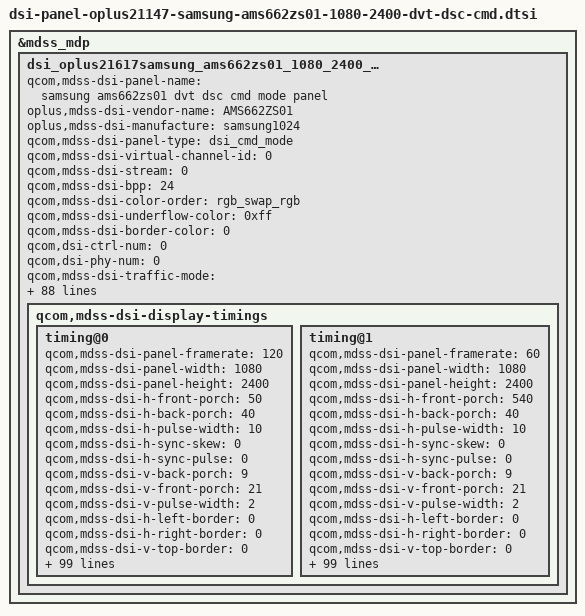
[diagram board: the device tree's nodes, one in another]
&mdss_mdp {
	dsi_oplus21617samsung_ams662zs01_1080_2400_cmd_dvt: qcom,mdss_dsi_oplus21617samsung_ams662zs01_1080_2400_cmd_dvt {
		qcom,mdss-dsi-panel-name = "samsung ams662zs01 dvt dsc cmd mode panel";
		oplus,mdss-dsi-vendor-name = "AMS662ZS01";
		oplus,mdss-dsi-manufacture = "samsung1024";
		qcom,mdss-dsi-panel-type = "dsi_cmd_mode";
		qcom,mdss-dsi-virtual-channel-id = <0>;
		qcom,mdss-dsi-stream = <0>;
		qcom,mdss-dsi-bpp = <24>;
		qcom,mdss-dsi-color-order = "rgb_swap_rgb";
		qcom,mdss-dsi-underflow-color = <0xff>;
		qcom,mdss-dsi-border-color = <0>;
		qcom,dsi-ctrl-num = <0>;
		qcom,dsi-phy-num = <0>;
		qcom,mdss-dsi-traffic-mode = "non_burst_sync_event";
		qcom,mdss-dsi-lane-map = "lane_map_0123";
		qcom,mdss-dsi-bllp-eof-power-mode;
		qcom,mdss-dsi-bllp-power-mode;
		qcom,mdss-dsi-lane-0-state;
		qcom,mdss-dsi-lane-1-state;
		qcom,mdss-dsi-lane-2-state;
		qcom,mdss-dsi-lane-3-state;
		qcom,mdss-dsi-dma-trigger = "trigger_sw";
		qcom,mdss-dsi-mdp-trigger = "none";
		qcom,mdss-dsi-reset-sequence = <1 10>, <0 10>, <1 10>;

		qcom,mdss-dsi-te-pin-select = <1>;
		qcom,mdss-dsi-te-dcs-command = <1>;
		qcom,mdss-dsi-te-check-enable;
		qcom,mdss-dsi-te-using-te-pin;
		qcom,mdss-dsi-lp11-init;
		qcom,mdss-dsi-wr-mem-start = <0x2c>;
		qcom,mdss-dsi-wr-mem-continue = <0x3c>;
		qcom,mdss-dsi-panel-hdr-enabled;
		qcom,mdss-dsi-panel-hdr-color-primaries = <15635 16450 34000 16000 13250 34500 7500 3000>;
		qcom,mdss-dsi-panel-peak-brightness = <5400000>;
		qcom,mdss-dsi-panel-blackness-level = <2000>;
		qcom,mdss-pan-physical-width-dimension = <70>;
		qcom,mdss-pan-physical-height-dimension = <153>;
		qcom,esd-check-enabled;
		qcom,mdss-dsi-panel-status-check-mode = "reg_read";
		qcom,mdss-dsi-panel-status-command = [06 01 00 01 05 00 02 0A 00
							06 01 00 01 05 00 02 05 00
							06 01 00 01 05 00 02 03 00
							06 01 00 01 05 00 02 0e 00];
		qcom,mdss-dsi-panel-status-command-state = "dsi_lp_mode";
		qcom,mdss-dsi-panel-status-value = <0x9f 0x00 0x01 0x80>;
		qcom,mdss-dsi-panel-status-read-length = <1 1 1 1>;
		oplus,esd-check-flag-enabled;
		oplus,esd-err-flag-gpio = <&tlmm 84 0>;
		oplus,esd-err-trigger-polarity = <1>;
		qcom,dynamic-mode-switch-enabled;
		qcom,dynamic-mode-switch-type = "dynamic-resolution-switch-immediate";
		qcom,mdss-dsi-display-timings {
			timing@0 {
				qcom,mdss-dsi-panel-framerate = <120>;
//				qcom,mdss-dsi-panel-clockrate = <830000000>;
				qcom,mdss-dsi-panel-width = <1080>;
				qcom,mdss-dsi-panel-height = <2400>;
				qcom,mdss-dsi-h-front-porch = <50>;
				qcom,mdss-dsi-h-back-porch = <40>;
				qcom,mdss-dsi-h-pulse-width = <10>;
				qcom,mdss-dsi-h-sync-skew = <0>;
				qcom,mdss-dsi-h-sync-pulse = <0>;
				qcom,mdss-dsi-v-back-porch = <9>;
				qcom,mdss-dsi-v-front-porch = <21>;
				qcom,mdss-dsi-v-pulse-width = <2>;
				qcom,mdss-dsi-h-left-border = <0>;
				qcom,mdss-dsi-h-right-border = <0>;
				qcom,mdss-dsi-v-top-border = <0>;
				qcom,mdss-dsi-v-bottom-border = <0>;
				qcom,mdss-dsi-panel-jitter = <0x4 0x1>;

				oplus,fod-on-vblank = <0>;
				oplus,fod-off-vblank = <1>;
				qcom,mdss-dsi-timing-switch-command = [
					//120hz Transition
					39 01 00 00 00 00 03 F0 5A 5A
					39 01 00 00 00 00 03 60 08 00
					39 01 00 00 00 00 02 F7 0F
					39 01 00 00 00 00 03 F0 A5 A5
				];
				qcom,mdss-dsi-fps-switch-command = [
					39 01 00 00 00 00 03 F0 5A 5A
					39 01 00 00 00 00 03 B0 28 F2
					39 01 00 00 00 00 02 F2 CE
					39 01 00 00 00 00 04 B0 01 B4 65
					39 01 00 00 00 00 21 65 09 70 09 28 09 03 08 98 08 2C 07 BF 06 EA 06 12 05 3A 04 62 03 8B 02 B2 01 6D 00 28 00 28 00 28
					39 01 00 00 00 00 04 B0 00 28 F2
					39 01 00 00 00 00 02 F2 C6
					39 01 00 00 00 00 03 60 08 00
					39 01 00 00 00 00 03 B0 08 F2
					39 01 00 00 00 00 02 F2 04
					39 01 00 00 00 00 02 F7 0F
					39 01 00 00 00 00 03 F0 A5 A5
				];
				qcom,mdss-dsi-on-command = [
					//DSC Setting
					39 01 00 00 00 00 81 9E
					11 00 00 89 30 80 09 60
					04 38 00 1E 02 1C 02 1C
					02 00 02 0E 00 20 02 E3
					00 07 00 0C 03 50 03 64
					18 00 10 F0 03 0C 20 00
					06 0B 0B 33 0E 1C 2A 38
					46 54 62 69 70 77 79 7B
					7D 7E 01 02 01 00 09 40
					09 BE 19 FC 19 FA 19 F8
					1A 38 1A 78 1A B6 2A F6
					2B 34 2B 74 3B 74 6B F4
					00 00 00 00 00 00 00 00
					00 00 00 00 00 00 00 00
					00 00 00 00 00 00 00 00
					00 00 00 00 00 00 00 00
					00 00 00 00 00 00 00 00
					39 01 00 00 00 00 02 C2 14
					39 01 00 00 00 00 02 9D 01
					//Sleep Out(11h)
					05 01 00 00 79 00 01 11
					//TE ON
					39 01 00 00 00 00 02 35 00
					//CASET/PASET Setting
					39 01 00 00 00 00 05 2A 00 00 04 37
					39 01 00 00 00 00 05 2B 00 00 09 5F
					//FQ CON Setting
					39 01 00 00 00 00 03 F0 5A 5A
					39 01 00 00 00 00 03 B0 27 F2
					39 01 00 00 00 00 02 F2 00
					39 01 00 00 00 00 03 F0 A5 A5
					//Frequency Setting
					39 01 00 00 00 00 03 F0 5A 5A
					39 01 00 00 00 00 03 60 08 00
					39 01 00 00 00 00 02 F7 0F
					39 01 00 00 00 00 03 F0 A5 A5
					//Seed mode 0
					39 01 00 00 00 00 03 f0 5a 5a
					39 01 00 00 00 00 03 b0 03 8f
					39 01 00 00 00 00 02 8f 05
					39 01 00 00 00 00 03 b0 28 f2
					39 01 00 00 00 00 02 f2 ce
					39 01 00 00 00 00 04 b0 01 18 68
					39 01 00 00 00 00 0f 68 e2 1a 1a 1a 82 04 f0 80 00 00 00 00 ff 00
					39 01 00 00 00 00 04 b0 00 28 f2
					39 01 00 00 00 00 02 f2 c6
					39 01 00 00 00 00 03 f0 a5 a5
					39 01 00 00 00 00 03 f0 5a 5a
					39 01 00 00 00 00 04 72 2c 21 00
					39 01 00 00 00 00 02 f8 00
					39 01 00 00 00 00 02 5d 06
					39 01 00 00 00 00 02 62 00
					39 01 00 00 00 00 03 b0 01 62
					39 01 00 00 00 00 16 62 C3 02 00 10 F0 04 06 01 e0 26 e9 f2 f7 07 fc E5 F0 02 FE FF FF
					39 01 00 00 18 00 04 72 2c 01 00
					39 01 00 00 00 00 03 f0 a5 a5
					/*OSC*/
					//39 01 00 00 00 00 03 F0 5A 5A
					//39 01 00 00 00 00 03 FC 5A 5A
					//39 01 00 00 00 00 03 B0 66 C5
					//39 01 00 00 00 00 03 C5 00 8C
					//39 01 00 00 00 00 03 B0 2A C5
					//39 01 00 00 00 00 05 C5 0D 10 80 45
					//39 01 00 00 00 00 03 B0 2E C5
					//39 01 00 00 00 00 03 C5 73 64
					//39 01 00 00 00 00 03 F0 A5 A5
					//39 01 00 00 00 00 03 FC A5 A5
					//BACKLIGHT
					39 01 00 00 00 00 02 53 20    //1 frame
				];

				qcom,mdss-dsi-off-command= [
					/* AOD off */
					39 01 00 00 00 00 03 F0 5A 5A
					15 01 00 00 00 00 02 91 02
					15 01 00 00 00 00 02 53 20
					39 01 00 00 00 00 03 F0 A5 A5
					05 01 00 00 0B 00 01 28
					05 01 00 00 79 00 01 10];
				qcom,mdss-dsi-post-on-backlight = [
					/* Display On */
					05 01 00 00 00 00 01 29
				];
				qcom,mdss-dsi-hbm-on-command = [
					//hbm
					39 01 00 00 09 00 03 F0 5A 5A
					39 01 00 00 0B 00 03 51 07 FF
					39 01 00 00 00 00 03 91 02 00
					39 01 00 00 00 00 03 B0 02 90
					39 01 00 00 00 00 02 90 1C
					/* HBM Mode ON */
					39 01 00 00 00 00 02 53 E0
					39 01 00 00 00 00 03 51 0B FF
					39 01 00 00 00 00 03 F0 A5 A5
				];
				qcom,mdss-dsi-normal-hbm-on-command = [
					//hbm
					39 01 00 00 09 00 03 F0 5A 5A
					39 01 00 00 0B 00 03 51 07 FF
					39 01 00 00 00 00 03 91 02 00
					39 01 00 00 00 00 03 B0 02 90
					39 01 00 00 00 00 02 90 1C
					/* HBM Mode ON */
					39 01 00 00 00 00 02 53 E0
					39 01 00 00 00 00 03 51 0B FF
					39 01 00 00 00 00 03 F0 A5 A5
				];
				qcom,mdss-dsi-hbm-off-command = [
					39 01 00 00 00 00 03 F0 5A 5A
					15 01 00 00 00 00 02 53 20
					39 01 00 00 0B 00 03 51 07 FF
					39 01 00 00 00 00 03 91 02 01
					39 01 00 00 00 00 03 B0 02 90
					39 01 00 00 00 00 02 90 18
					39 01 00 00 00 00 03 F0 A5 A5
				];
				qcom,mdss-dsi-aod-hbm-on-command = [
					39 01 00 00 00 00 03 F0 5A 5A
					15 01 00 00 00 00 02 91 02
					39 01 00 00 00 00 02 53 20
					39 01 00 00 00 00 03 F0 A5 A5
					39 01 00 00 00 00 03 F0 5A 5A
					39 01 00 00 0A 00 03 51 07 FF
					39 01 00 00 00 00 03 91 02 00
					39 01 00 00 00 00 03 B0 02 90
					39 01 00 00 00 00 02 90 1C
					/* HBM Mode ON */
					39 01 00 00 00 00 02 53 E0
					39 01 00 00 00 00 03 51 0B FF
					39 01 00 00 00 00 03 F0 A5 A5
				];
				qcom,mdss-dsi-aod-hbm-off-command = [
					39 01 00 00 00 00 03 F0 5A 5A
					15 01 00 00 00 00 02 91 02
					15 01 00 00 00 00 02 53 20
					39 01 00 00 00 00 03 F0 A5 A5
					39 01 00 00 00 00 03 F0 5A 5A
					15 01 00 00 00 00 02 53 20
					39 01 00 00 0A 00 03 51 07 FF
					39 01 00 00 00 00 03 91 02 01
					39 01 00 00 00 00 03 B0 02 90
					39 01 00 00 00 00 02 90 18
					39 01 00 00 00 00 03 F0 A5 A5
				];
				qcom,mdss-dsi-aod-high-mode-command = [
					/* AOD 50nit */
					39 01 00 00 00 00 03 F0 5A 5A
					15 01 00 00 00 00 02 91 01
					15 01 00 00 00 00 02 53 24
					15 01 00 00 00 00 02 BB 1D
					39 01 00 00 00 00 03 F0 A5 A5
				];
				qcom,mdss-dsi-aod-low-mode-command = [
					/* AOD 10nit */
					39 01 00 00 00 00 03 F0 5A 5A
					15 01 00 00 00 00 02 91 01
					15 01 00 00 00 00 02 53 25
					15 01 00 00 00 00 02 BB 1D
					39 01 00 00 00 00 03 F0 A5 A5
				];
				qcom,mdss-dsi-lp1-command = [
					//05 01 00 00 25 00 01 28
					/*AOD on */
					39 01 00 00 00 00 03 F0 5A 5A
					15 01 00 00 00 00 02 91 01
					15 01 00 00 00 00 02 53 24
					15 01 00 00 00 00 02 BB 1D
					39 01 00 00 00 00 03 F0 A5 A5
				];
				qcom,mdss-dsi-nolp-command = [
					/* AOD off to normal*/
					39 01 00 00 00 00 03 F0 5A 5A
					15 01 00 00 00 00 02 91 02
					15 01 00 00 00 00 02 53 20
					39 01 00 00 00 00 03 F0 A5 A5
				];
				qcom,mdss-dsi-seed-off-command = [
					/* CRC OFF */
					39 01 00 00 00 00 03 F0 5A 5A
					15 01 00 00 00 00 02 5D 00
					15 01 00 00 00 00 02 62 01
					39 01 00 00 00 00 03 F0 A5 A5
				];
				qcom,mdss-dsi-seed-3-command = [
					39 01 00 00 00 00 03 F0 5A 5A
					39 01 00 00 00 00 03 B0 03 8F
					39 01 00 00 00 00 02 8F 25
					39 01 00 00 00 00 03 B0 14 8F
					39 01 00 00 00 00 0E 8F 06 1C 1E 1B 25 28 24 2C 30 2A 2F 33 2D
					39 01 00 00 00 00 03 B0 28 F2
					39 01 00 00 00 00 02 F2 CE
					39 01 00 00 00 00 04 B0 01 18 68
					39 01 00 00 00 00 09 68 E2 1A 1A 1A 92 0C D2 80
					39 01 00 00 00 00 04 B0 01 20 68
					39 01 00 00 00 00 07 68 00 00 00 00 FF 90
					39 01 00 00 00 00 04 B0 00 28 F2
					39 01 00 00 00 00 02 F2 C6
					39 01 00 00 00 00 03 F0 A5 A5
					39 01 00 00 00 00 03 F0 5A 5A
					39 01 00 00 00 00 04 72 2C 21 00
					39 01 00 00 00 00 02 F8 00
					39 01 00 00 00 00 02 5D 06
					39 01 00 00 00 00 02 62 00
					39 01 00 00 00 00 03 B0 01 62
					39 01 00 00 00 00 16 62 FA 04 00 00 F6 04 0F 01 E0 26 E9 F2 F7 07 FC D0 DE 02 FF FD FF
					39 01 00 00 18 00 04 72 2C 01 00
					39 01 00 00 00 00 03 F0 A5 A5
				];
				qcom,mdss-dsi-seed-2-command = [
					39 01 00 00 00 00 03 F0 5A 5A
					39 01 00 00 00 00 03 B0 03 8F
					39 01 00 00 00 00 02 8F 25
					39 01 00 00 00 00 03 B0 14 8F
					39 01 00 00 00 00 0E 8F 06 1C 1E 1B 25 28 24 2C 30 2A 2F 33 2D
					39 01 00 00 00 00 03 B0 28 F2
					39 01 00 00 00 00 02 F2 CE
					39 01 00 00 00 00 04 B0 01 18 68
					39 01 00 00 00 00 09 68 E2 1A 1A 1A 92 0C D2 80
					39 01 00 00 00 00 04 B0 01 20 68
					39 01 00 00 00 00 07 68 DA AE 00 00 FF 90
					39 01 00 00 00 00 04 B0 00 28 F2
					39 01 00 00 00 00 02 F2 C6
					39 01 00 00 00 00 03 F0 A5 A5
					39 01 00 00 00 00 03 F0 5A 5A
					39 01 00 00 00 00 04 72 2C 21 00
					39 01 00 00 00 00 02 F8 00
					39 01 00 00 00 00 02 5D 06
					39 01 00 00 00 00 02 62 00
					39 01 00 00 00 00 03 B0 01 62
					39 01 00 00 00 00 16 62 FF 00 00 00 FF 00 00 00 FF 00 FF FF FF 00 FF FF FF 00 FF FF FF
					39 01 00 00 18 00 04 72 2C 01 00
					39 01 00 00 00 00 03 F0 A5 A5
				];
				qcom,mdss-dsi-seed-1-command = [
					39 01 00 00 00 00 03 F0 5A 5A
					39 01 00 00 00 00 03 B0 03 8F
					39 01 00 00 00 00 02 8F 25
					39 01 00 00 00 00 03 B0 14 8F
					39 01 00 00 00 00 0E 8F 06 1C 1E 1B 25 28 24 2C 30 2A 2F 33 2D
					39 01 00 00 00 00 03 B0 28 F2
					39 01 00 00 00 00 02 F2 CE
					39 01 00 00 00 00 04 B0 01 18 68
					39 01 00 00 00 00 09 68 E2 1A 1A 1A 92 0C D2 80
					39 01 00 00 00 00 04 B0 01 20 68
					39 01 00 00 00 00 07 68 00 00 00 00 FF 90
					39 01 00 00 00 00 04 B0 00 28 F2
					39 01 00 00 00 00 02 F2 C6
					39 01 00 00 00 00 03 F0 A5 A5
					39 01 00 00 00 00 03 F0 5A 5A
					39 01 00 00 00 00 04 72 2C 21 00
					39 01 00 00 00 00 02 F8 00
					39 01 00 00 00 00 02 5D 06
					39 01 00 00 00 00 02 62 00
					39 01 00 00 00 00 03 B0 01 62
					39 01 00 00 00 00 16 62 FA 04 00 00 F6 04 0F 01 E0 26 E9 F2 F7 07 FC D0 DE 02 FF FD FF
					39 01 00 00 18 00 04 72 2C 01 00
					39 01 00 00 00 00 03 F0 A5 A5
				];
				qcom,mdss-dsi-seed-0-command = [
					39 01 00 00 00 00 03 f0 5a 5a
					39 01 00 00 00 00 03 b0 03 8f
					39 01 00 00 00 00 02 8f 05
					39 01 00 00 00 00 03 b0 28 f2
					39 01 00 00 00 00 02 f2 ce
					39 01 00 00 00 00 04 b0 01 18 68
					39 01 00 00 00 00 0f 68 e2 1a 1a 1a 82 04 f0 80 00 00 00 00 ff 00
					39 01 00 00 00 00 04 b0 00 28 f2
					39 01 00 00 00 00 02 f2 c6
					39 01 00 00 00 00 03 f0 a5 a5
					39 01 00 00 00 00 03 f0 5a 5a
					39 01 00 00 00 00 04 72 2c 21 00
					39 01 00 00 00 00 02 f8 00
					39 01 00 00 00 00 02 5d 06
					39 01 00 00 00 00 02 62 00
					39 01 00 00 00 00 03 b0 01 62
					39 01 00 00 00 00 16 62 C3 02 00 10 F0 04 06 01 e0 26 e9 f2 f7 07 fc E5 F0 02 FE FF FF
					39 01 00 00 18 00 04 72 2c 01 00
					39 01 00 00 00 00 03 f0 a5 a5
				];
				qcom,mdss-dsi-no-seed-native-command = [ //loading off seed CRC off
					39 01 00 00 00 00 03 F0 5A 5A
					39 01 00 00 00 00 03 B0 03 8F
					39 01 00 00 00 00 02 8F 05
					39 01 00 00 00 00 03 B0 28 F2
					39 01 00 00 00 00 02 F2 CE
					39 01 00 00 00 00 04 B0 01 18 68
					39 01 00 00 00 00 0F 68 E2 1A 1A 1A 82 04 F0 80 00 00 00 00 FF 00
					39 01 00 00 00 00 04 B0 00 28 F2
					39 01 00 00 00 00 02 F2 C6
					39 01 00 00 00 00 03 F0 A5 A5
					39 01 00 00 00 00 03 F0 5A 5A
					15 01 00 00 00 00 02 5D 00
					15 01 00 00 00 00 02 62 01
					39 01 00 00 00 00 03 F0 A5 A5
				];
				qcom,mdss-dsi-hbm-enter-switch-command = [
					39 00 00 00 00 00 03 F0 5A 5A
					39 00 00 00 00 00 03 51 07 FF
					39 01 00 00 0A 00 03 F0 A5 A5
					39 00 00 00 00 00 03 F0 5A 5A
					39 00 00 00 00 00 03 91 02 00
					39 00 00 00 00 00 03 B0 02 90
					15 00 00 00 00 00 02 90 1C
					/* HBM Mode ON */
					15 00 00 00 00 00 02 53 E0
					39 00 00 00 00 00 03 51 08 00
					39 01 00 00 00 00 03 F0 A5 A5
				];
				qcom,mdss-dsi-hbm-exit-switch-command = [
					39 00 00 00 00 00 03 F0 5A 5A
					15 00 00 00 00 00 02 53 20
					39 00 00 00 00 00 03 51 07 FF
					39 01 00 00 0A 00 03 F0 A5 A5
					39 00 00 00 00 00 03 F0 5A 5A
					39 00 00 00 00 00 03 91 02 01
					39 00 00 00 00 00 03 B0 02 90
					15 00 00 00 00 00 02 90 18
					39 00 00 00 00 00 03 51 07 FF
					39 01 00 00 00 00 03 F0 A5 A5
				];
				qcom,mdss-dsi-osc-clk-mode0-command = [
					/*OSC 415 + 180.3*/
					39 01 00 00 00 00 03 F0 5A 5A
					39 01 00 00 00 00 03 FC 5A 5A
					39 01 00 00 00 00 03 B0 2A C5
					39 01 00 00 00 00 05 C5 0D 10 80 45
					39 01 00 00 00 00 03 B0 2E C5
					39 01 00 00 00 00 03 C5 6F 39
					39 01 00 00 00 00 03 F0 A5 A5
					39 01 00 00 00 00 03 FC A5 A5
				];
				qcom,mdss-dsi-osc-clk-mode1-command = [
					/*OSC 415 + 182.3*/
					39 01 00 00 00 00 03 F0 5A 5A
					39 01 00 00 00 00 03 FC 5A 5A
					39 01 00 00 00 00 03 B0 2A C5
					39 01 00 00 00 00 05 C5 0D 10 80 45
					39 01 00 00 00 00 03 B0 2E C5
					39 01 00 00 00 00 03 C5 70 74
					39 01 00 00 00 00 03 F0 A5 A5
					39 01 00 00 00 00 03 FC A5 A5
				];
				qcom,mdss-dsi-no-seed-native-command-state = "dsi_hs_mode";
				qcom,mdss-dsi-timing-switch-command-state = "dsi_hs_mode";
				qcom,mdss-dsi-on-command-state = "dsi_lp_mode";
				qcom,mdss-dsi-off-command-state = "dsi_hs_mode";
				qcom,mdss-dsi-hbm-on-command-state = "dsi_hs_mode";
				qcom,mdss-dsi-hbm-off-command-state = "dsi_hs_mode";
				qcom,mdss-dsi-aod-hbm-on-command-state = "dsi_hs_mode";
				qcom,mdss-dsi-aod-hbm-off-command-state = "dsi_hs_mode";
				qcom,mdss-dsi-osc-clk-mode0-command-state = "dsi_hs_mode";
				qcom,mdss-dsi-osc-clk-mode1-command-state = "dsi_hs_mode";
				qcom,mdss-dsi-seed-0-command-state = "dsi_hs_mode";
				qcom,mdss-dsi-seed-1-command-state = "dsi_hs_mode";
				qcom,mdss-dsi-seed-2-command-state = "dsi_hs_mode";
				qcom,mdss-dsi-seed-3-command-state = "dsi_hs_mode";
				qcom,mdss-dsi-seed-off-command-state = "dsi_hs_mode";
				qcom,mdss-dsi-seed-0-switch-command-state = "dsi_hs_mode";
				qcom,mdss-dsi-seed-1-switch-command-state = "dsi_hs_mode";
				qcom,mdss-dsi-seed-2-switch-command-state = "dsi_hs_mode";
				qcom,mdss-dsi-fps-switch-command-state = "dsi_hs_mode";
				qcom,compression-mode = "dsc";
				qcom,mdss-dsc-slice-height = <30>;
				qcom,mdss-dsc-slice-width = <540>;
				qcom,mdss-dsc-slice-per-pkt = <2>;
				qcom,mdss-dsc-bit-per-component = <8>;
				qcom,mdss-dsc-bit-per-pixel = <8>;
				qcom,mdss-dsc-block-prediction-enable;
			};

			timing@1 {
				qcom,mdss-dsi-panel-framerate = <60>;
//				qcom,mdss-dsi-panel-clockrate = <830000000>;
				qcom,mdss-dsi-panel-width = <1080>;
				qcom,mdss-dsi-panel-height = <2400>;
				qcom,mdss-dsi-h-front-porch = <540>;
				qcom,mdss-dsi-h-back-porch = <40>;
				qcom,mdss-dsi-h-pulse-width = <10>;
				qcom,mdss-dsi-h-sync-skew = <0>;
				qcom,mdss-dsi-h-sync-pulse = <0>;
				qcom,mdss-dsi-v-back-porch = <9>;
				qcom,mdss-dsi-v-front-porch = <21>;
				qcom,mdss-dsi-v-pulse-width = <2>;
				qcom,mdss-dsi-h-left-border = <0>;
				qcom,mdss-dsi-h-right-border = <0>;
				qcom,mdss-dsi-v-top-border = <0>;
				qcom,mdss-dsi-v-bottom-border = <0>;
				qcom,mdss-dsi-panel-jitter = <0x4 0x1>;

				oplus,fod-on-vblank = <0>;
				oplus,fod-off-vblank = <1>;
				qcom,mdss-dsi-timing-switch-command = [
					//60hz Transition
					39 01 00 00 00 00 03 F0 5A 5A
					39 01 00 00 00 00 03 60 00 00
					39 01 00 00 00 00 02 F7 0F
					39 01 00 00 11 00 03 F0 A5 A5
				];
				qcom,mdss-dsi-fps-switch-command = [
					39 01 00 00 00 00 03 F0 5A 5A
					39 01 00 00 00 00 03 B0 28 F2
					39 01 00 00 00 00 02 F2 CE
					39 01 00 00 00 00 04 B0 01 B4 65
					39 01 00 00 00 00 21 65 09 70 09 28 09 03 08 98 08 2C 07 BF 06 EA 06 12 05 3A 04 62 03 8B 02 B2 01 6D 00 28 00 28 00 28
					39 01 00 00 00 00 04 B0 00 28 F2
					39 01 00 00 00 00 02 F2 C6
					39 01 00 00 00 00 03 60 00 00
					39 01 00 00 00 00 03 B0 08 F2
					39 01 00 00 00 00 02 F2 04
					39 01 00 00 00 00 02 F7 0F
					39 01 00 00 11 00 03 F0 A5 A5
				];
				qcom,mdss-dsi-on-command = [
					//DSC Setting
					39 01 00 00 00 00 81 9E
					11 00 00 89 30 80 09 60
					04 38 00 1E 02 1C 02 1C
					02 00 02 0E 00 20 02 E3
					00 07 00 0C 03 50 03 64
					18 00 10 F0 03 0C 20 00
					06 0B 0B 33 0E 1C 2A 38
					46 54 62 69 70 77 79 7B
					7D 7E 01 02 01 00 09 40
					09 BE 19 FC 19 FA 19 F8
					1A 38 1A 78 1A B6 2A F6
					2B 34 2B 74 3B 74 6B F4
					00 00 00 00 00 00 00 00
					00 00 00 00 00 00 00 00
					00 00 00 00 00 00 00 00
					00 00 00 00 00 00 00 00
					00 00 00 00 00 00 00 00
					39 01 00 00 00 00 02 C2 14
					39 01 00 00 00 00 02 9D 01
					//Sleep Out(11h)
					05 01 00 00 79 00 01 11
					//TE ON
					39 01 00 00 00 00 02 35 00
					//CASET/PASET Setting
					39 01 00 00 00 00 05 2A 00 00 04 37
					39 01 00 00 00 00 05 2B 00 00 09 5F
					//FQ CON Setting
					39 01 00 00 00 00 03 F0 5A 5A
					39 01 00 00 00 00 03 B0 27 F2
					39 01 00 00 00 00 02 F2 00
					39 01 00 00 00 00 03 F0 A5 A5
					//Frequency Setting
					39 01 00 00 00 00 03 F0 5A 5A
					39 01 00 00 00 00 03 60 00 00
					39 01 00 00 00 00 02 F7 0F
					39 01 00 00 00 00 03 F0 A5 A5
					//Seed mode 0
					39 01 00 00 00 00 03 f0 5a 5a
					39 01 00 00 00 00 03 b0 03 8f
					39 01 00 00 00 00 02 8f 05
					39 01 00 00 00 00 03 b0 28 f2
					39 01 00 00 00 00 02 f2 ce
					39 01 00 00 00 00 04 b0 01 18 68
					39 01 00 00 00 00 0f 68 e2 1a 1a 1a 82 04 f0 80 00 00 00 00 ff 00
					39 01 00 00 00 00 04 b0 00 28 f2
					39 01 00 00 00 00 02 f2 c6
					39 01 00 00 00 00 03 f0 a5 a5
					39 01 00 00 00 00 03 f0 5a 5a
					39 01 00 00 00 00 04 72 2c 21 00
					39 01 00 00 00 00 02 f8 00
					39 01 00 00 00 00 02 5d 06
					39 01 00 00 00 00 02 62 00
					39 01 00 00 00 00 03 b0 01 62
					39 01 00 00 00 00 16 62 C3 02 00 10 F0 04 06 01 e0 26 e9 f2 f7 07 fc E5 F0 02 FE FF FF
					39 01 00 00 18 00 04 72 2c 01 00
					39 01 00 00 00 00 03 f0 a5 a5
					/*OSC*/
					//39 01 00 00 00 00 03 F0 5A 5A
					//39 01 00 00 00 00 03 FC 5A 5A
					//39 01 00 00 00 00 03 B0 66 C5
					//39 01 00 00 00 00 03 C5 00 8C
					//39 01 00 00 00 00 03 B0 2A C5
					//39 01 00 00 00 00 05 C5 0D 10 80 45
					//39 01 00 00 00 00 03 B0 2E C5
					//39 01 00 00 00 00 03 C5 73 64
					//39 01 00 00 00 00 03 F0 A5 A5
					//39 01 00 00 00 00 03 FC A5 A5
					//loading effect on
					//39 01 00 00 00 00 03 F0 5A 5A
					//39 01 00 00 00 00 03 B0 03 8F
					//39 01 00 00 00 00 02 8F 25
					//39 01 00 00 00 00 03 B0 28 F2
					//39 01 00 00 00 00 02 F2 CE
					//39 01 00 00 00 00 04 B0 01 18 68
					//39 01 00 00 00 00 0F 68 E2 1A 1A 1A 82 04 F0 80 00 00 00 00 FF 00
					//39 01 00 00 00 00 04 B0 00 28 F2
					//39 01 00 00 00 00 02 F2 C6
					//39 01 00 00 00 00 03 F0 A5 A5
					//BACKLIGHT
					39 01 00 00 00 00 02 53 20    //1 frame
				];

				qcom,mdss-dsi-off-command= [
					/* AOD off */
					39 01 00 00 00 00 03 F0 5A 5A
					15 01 00 00 00 00 02 91 02
					15 01 00 00 00 00 02 53 20
					39 01 00 00 00 00 03 F0 A5 A5
					05 01 00 00 0B 00 01 28
					05 01 00 00 79 00 01 10];
				qcom,mdss-dsi-post-on-backlight = [
					/* Display On */
					05 01 00 00 00 00 01 29
				];
				qcom,mdss-dsi-hbm-on-command = [
					//hbm
					39 01 00 00 00 00 03 F0 5A 5A
					39 01 00 00 0A 00 03 51 07 FF
					39 01 00 00 00 00 03 91 02 00
					39 01 00 00 00 00 03 B0 02 90
					39 01 00 00 00 00 02 90 1C
					/* HBM Mode ON */
					39 01 00 00 00 00 02 53 E0
					39 01 00 00 00 00 03 51 0B FF
					39 01 00 00 00 00 03 F0 A5 A5
				];
				qcom,mdss-dsi-normal-hbm-on-command = [
					//hbm
					39 01 00 00 00 00 03 F0 5A 5A
					39 01 00 00 14 00 03 51 07 FF
					39 01 00 00 00 00 03 91 02 00
					39 01 00 00 00 00 03 B0 02 90
					39 01 00 00 00 00 02 90 1C
					/* HBM Mode ON */
					39 01 00 00 00 00 02 53 E0
					39 01 00 00 00 00 03 51 0B FF
					39 01 00 00 00 00 03 F0 A5 A5
				];
				qcom,mdss-dsi-hbm-off-command = [
					39 01 00 00 00 00 03 F0 5A 5A
					15 01 00 00 00 00 02 53 20
					39 01 00 00 14 00 03 51 07 FF
					39 01 00 00 00 00 03 91 02 01
					39 01 00 00 00 00 03 B0 02 90
					39 01 00 00 00 00 02 90 18
					39 01 00 00 00 00 03 F0 A5 A5
				];
				qcom,mdss-dsi-aod-hbm-on-command = [
					39 01 00 00 00 00 03 F0 5A 5A
					15 01 00 00 00 00 02 91 02
					39 01 00 00 00 00 02 53 20
					39 01 00 00 00 00 03 F0 A5 A5
					39 01 00 00 00 00 03 F0 5A 5A
					39 01 00 00 14 00 03 51 07 FF
					39 01 00 00 00 00 03 91 02 00
					39 01 00 00 00 00 03 B0 02 90
					39 01 00 00 00 00 02 90 1C
					/* HBM Mode ON */
					39 01 00 00 00 00 02 53 E0
					39 01 00 00 00 00 03 51 0B FF
					39 01 00 00 00 00 03 F0 A5 A5
				];
				qcom,mdss-dsi-aod-hbm-off-command = [
					39 01 00 00 00 00 03 F0 5A 5A
					15 01 00 00 00 00 02 91 02
					15 01 00 00 00 00 02 53 20
					39 01 00 00 00 00 03 F0 A5 A5
					39 01 00 00 00 00 03 F0 5A 5A
					15 01 00 00 00 00 02 53 20
					39 01 00 00 0A 00 03 51 07 FF
					39 01 00 00 00 00 03 91 02 01
					39 01 00 00 00 00 03 B0 02 90
					39 01 00 00 00 00 02 90 18
					39 01 00 00 00 00 03 F0 A5 A5
				];
				qcom,mdss-dsi-aod-high-mode-command = [
					/* AOD 50nit */
					39 01 00 00 00 00 03 F0 5A 5A
					15 01 00 00 00 00 02 91 01
					15 01 00 00 00 00 02 53 24
					15 01 00 00 00 00 02 BB 1D
					39 01 00 00 00 00 03 F0 A5 A5
				];
				qcom,mdss-dsi-aod-low-mode-command = [
					/* AOD 10nit */
					39 01 00 00 00 00 03 F0 5A 5A
					15 01 00 00 00 00 02 91 01
					15 01 00 00 00 00 02 53 25
					15 01 00 00 00 00 02 BB 1D
					39 01 00 00 00 00 03 F0 A5 A5
				];
				qcom,mdss-dsi-lp1-command = [
					//05 01 00 00 25 00 01 28
					/*AOD on */
					39 01 00 00 00 00 03 F0 5A 5A
					15 01 00 00 00 00 02 91 01
					15 01 00 00 00 00 02 53 24
					15 01 00 00 00 00 02 BB 1D
					39 01 00 00 00 00 03 F0 A5 A5
				];
				qcom,mdss-dsi-nolp-command = [
					/* AOD off to normal*/
					39 01 00 00 00 00 03 F0 5A 5A
					15 01 00 00 00 00 02 91 02
					15 01 00 00 00 00 02 53 20
					39 01 00 00 00 00 03 F0 A5 A5
				];
				qcom,mdss-dsi-seed-off-command = [
					/* CRC OFF */
					39 01 00 00 00 00 03 F0 5A 5A
					15 01 00 00 00 00 02 5D 00
					15 01 00 00 00 00 02 62 01
					39 01 00 00 00 00 03 F0 A5 A5
				];
				qcom,mdss-dsi-seed-3-command = [
					39 01 00 00 00 00 03 F0 5A 5A
					39 01 00 00 00 00 03 B0 03 8F
					39 01 00 00 00 00 02 8F 25
					39 01 00 00 00 00 03 B0 14 8F
					39 01 00 00 00 00 0E 8F 06 1C 1E 1B 25 28 24 2C 30 2A 2F 33 2D
					39 01 00 00 00 00 03 B0 28 F2
					39 01 00 00 00 00 02 F2 CE
					39 01 00 00 00 00 04 B0 01 18 68
					39 01 00 00 00 00 09 68 E2 1A 1A 1A 92 0C D2 80
					39 01 00 00 00 00 04 B0 01 20 68
					39 01 00 00 00 00 07 68 00 00 00 00 FF 90
					39 01 00 00 00 00 04 B0 00 28 F2
					39 01 00 00 00 00 02 F2 C6
					39 01 00 00 00 00 03 F0 A5 A5
					39 01 00 00 00 00 03 F0 5A 5A
					39 01 00 00 00 00 04 72 2C 21 00
					39 01 00 00 00 00 02 F8 00
					39 01 00 00 00 00 02 5D 06
					39 01 00 00 00 00 02 62 00
					39 01 00 00 00 00 03 B0 01 62
					39 01 00 00 00 00 16 62 FA 04 00 00 F6 04 0F 01 E0 26 E9 F2 F7 07 FC D0 DE 02 FF FD FF
					39 01 00 00 18 00 04 72 2C 01 00
					39 01 00 00 00 00 03 F0 A5 A5
				];
				qcom,mdss-dsi-seed-2-command = [
					39 01 00 00 00 00 03 F0 5A 5A
					39 01 00 00 00 00 03 B0 03 8F
					39 01 00 00 00 00 02 8F 25
					39 01 00 00 00 00 03 B0 14 8F
					39 01 00 00 00 00 0E 8F 06 1C 1E 1B 25 28 24 2C 30 2A 2F 33 2D
					39 01 00 00 00 00 03 B0 28 F2
					39 01 00 00 00 00 02 F2 CE
					39 01 00 00 00 00 04 B0 01 18 68
					39 01 00 00 00 00 09 68 E2 1A 1A 1A 92 0C D2 80
					39 01 00 00 00 00 04 B0 01 20 68
					39 01 00 00 00 00 07 68 DA AE 00 00 FF 90
					39 01 00 00 00 00 04 B0 00 28 F2
					39 01 00 00 00 00 02 F2 C6
					39 01 00 00 00 00 03 F0 A5 A5
					39 01 00 00 00 00 03 F0 5A 5A
					39 01 00 00 00 00 04 72 2C 21 00
					39 01 00 00 00 00 02 F8 00
					39 01 00 00 00 00 02 5D 06
					39 01 00 00 00 00 02 62 00
					39 01 00 00 00 00 03 B0 01 62
					39 01 00 00 00 00 16 62 FF 00 00 00 FF 00 00 00 FF 00 FF FF FF 00 FF FF FF 00 FF FF FF
					39 01 00 00 18 00 04 72 2C 01 00
					39 01 00 00 00 00 03 F0 A5 A5
				];
				qcom,mdss-dsi-seed-1-command = [
					39 01 00 00 00 00 03 F0 5A 5A
					39 01 00 00 00 00 03 B0 03 8F
					39 01 00 00 00 00 02 8F 25
					39 01 00 00 00 00 03 B0 14 8F
					39 01 00 00 00 00 0E 8F 06 1C 1E 1B 25 28 24 2C 30 2A 2F 33 2D
					39 01 00 00 00 00 03 B0 28 F2
					39 01 00 00 00 00 02 F2 CE
					39 01 00 00 00 00 04 B0 01 18 68
					39 01 00 00 00 00 09 68 E2 1A 1A 1A 92 0C D2 80
					39 01 00 00 00 00 04 B0 01 20 68
					39 01 00 00 00 00 07 68 00 00 00 00 FF 90
					39 01 00 00 00 00 04 B0 00 28 F2
					39 01 00 00 00 00 02 F2 C6
					39 01 00 00 00 00 03 F0 A5 A5
					39 01 00 00 00 00 03 F0 5A 5A
					39 01 00 00 00 00 04 72 2C 21 00
					39 01 00 00 00 00 02 F8 00
					39 01 00 00 00 00 02 5D 06
					39 01 00 00 00 00 02 62 00
					39 01 00 00 00 00 03 B0 01 62
					39 01 00 00 00 00 16 62 FA 04 00 00 F6 04 0F 01 E0 26 E9 F2 F7 07 FC D0 DE 02 FF FD FF
					39 01 00 00 18 00 04 72 2C 01 00
					39 01 00 00 00 00 03 F0 A5 A5
				];
				qcom,mdss-dsi-seed-0-command = [
					39 01 00 00 00 00 03 f0 5a 5a
					39 01 00 00 00 00 03 b0 03 8f
					39 01 00 00 00 00 02 8f 05
					39 01 00 00 00 00 03 b0 28 f2
					39 01 00 00 00 00 02 f2 ce
					39 01 00 00 00 00 04 b0 01 18 68
					39 01 00 00 00 00 0f 68 e2 1a 1a 1a 82 04 f0 80 00 00 00 00 ff 00
					39 01 00 00 00 00 04 b0 00 28 f2
					39 01 00 00 00 00 02 f2 c6
					39 01 00 00 00 00 03 f0 a5 a5
					39 01 00 00 00 00 03 f0 5a 5a
					39 01 00 00 00 00 04 72 2c 21 00
					39 01 00 00 00 00 02 f8 00
					39 01 00 00 00 00 02 5d 06
					39 01 00 00 00 00 02 62 00
					39 01 00 00 00 00 03 b0 01 62
					39 01 00 00 00 00 16 62 C3 02 00 10 F0 04 06 01 e0 26 e9 f2 f7 07 fc E5 F0 02 FE FF FF
					39 01 00 00 18 00 04 72 2c 01 00
					39 01 00 00 00 00 03 f0 a5 a5
				];
				qcom,mdss-dsi-no-seed-native-command = [ //loading off seed CRC off
					39 01 00 00 00 00 03 F0 5A 5A
					39 01 00 00 00 00 03 B0 03 8F
					39 01 00 00 00 00 02 8F 05
					39 01 00 00 00 00 03 B0 28 F2
					39 01 00 00 00 00 02 F2 CE
					39 01 00 00 00 00 04 B0 01 18 68
					39 01 00 00 00 00 0F 68 E2 1A 1A 1A 82 04 F0 80 00 00 00 00 FF 00
					39 01 00 00 00 00 04 B0 00 28 F2
					39 01 00 00 00 00 02 F2 C6
					39 01 00 00 00 00 03 F0 A5 A5
					39 01 00 00 00 00 03 F0 5A 5A
					15 01 00 00 00 00 02 5D 00
					15 01 00 00 00 00 02 62 01
					39 01 00 00 00 00 03 F0 A5 A5
				];
				qcom,mdss-dsi-hbm-enter-switch-command = [
					39 00 00 00 00 00 03 F0 5A 5A
					39 00 00 00 00 00 03 51 07 FF
					39 01 00 00 14 00 03 F0 A5 A5
					39 00 00 00 00 00 03 F0 5A 5A
					39 00 00 00 00 00 03 91 02 00
					39 00 00 00 00 00 03 B0 02 90
					15 00 00 00 00 00 02 90 1C
					/* HBM Mode ON */
					15 00 00 00 00 00 02 53 E0
					39 00 00 00 00 00 03 51 08 00
					39 01 00 00 00 00 03 F0 A5 A5
				];
				qcom,mdss-dsi-hbm-exit-switch-command = [
					39 00 00 00 00 00 03 F0 5A 5A
					15 00 00 00 00 00 02 53 20
					39 00 00 00 00 00 03 51 07 FF
					39 01 00 00 14 00 03 F0 A5 A5
					39 00 00 00 00 00 03 F0 5A 5A
					39 00 00 00 00 00 03 91 02 01
					39 00 00 00 00 00 03 B0 02 90
					15 00 00 00 00 00 02 90 18
					39 00 00 00 00 00 03 51 07 FF
					39 01 00 00 00 00 03 F0 A5 A5
				];
				qcom,mdss-dsi-osc-clk-mode0-command = [
					/*OSC 415 + 180.3*/
					39 01 00 00 00 00 03 F0 5A 5A
					39 01 00 00 00 00 03 FC 5A 5A
					39 01 00 00 00 00 03 B0 2A C5
					39 01 00 00 00 00 05 C5 0D 10 80 45
					39 01 00 00 00 00 03 B0 2E C5
					39 01 00 00 00 00 03 C5 6F 39
					39 01 00 00 00 00 03 F0 A5 A5
					39 01 00 00 00 00 03 FC A5 A5
				];
				qcom,mdss-dsi-osc-clk-mode1-command = [
					/*OSC 415 + 182.3*/
					39 01 00 00 00 00 03 F0 5A 5A
					39 01 00 00 00 00 03 FC 5A 5A
					39 01 00 00 00 00 03 B0 2A C5
					39 01 00 00 00 00 05 C5 0D 10 80 45
					39 01 00 00 00 00 03 B0 2E C5
					39 01 00 00 00 00 03 C5 70 74
					39 01 00 00 00 00 03 F0 A5 A5
					39 01 00 00 00 00 03 FC A5 A5
				];
				qcom,mdss-dsi-no-seed-native-command-state = "dsi_hs_mode";
				qcom,mdss-dsi-timing-switch-command-state = "dsi_hs_mode";
				qcom,mdss-dsi-on-command-state = "dsi_lp_mode";
				qcom,mdss-dsi-off-command-state = "dsi_hs_mode";
				qcom,mdss-dsi-hbm-on-command-state = "dsi_hs_mode";
				qcom,mdss-dsi-hbm-off-command-state = "dsi_hs_mode";
				qcom,mdss-dsi-aod-hbm-on-command-state = "dsi_hs_mode";
				qcom,mdss-dsi-aod-hbm-off-command-state = "dsi_hs_mode";
				qcom,mdss-dsi-osc-clk-mode0-command-state = "dsi_hs_mode";
				qcom,mdss-dsi-osc-clk-mode1-command-state = "dsi_hs_mode";
				qcom,mdss-dsi-seed-0-command-state = "dsi_hs_mode";
				qcom,mdss-dsi-seed-1-command-state = "dsi_hs_mode";
				qcom,mdss-dsi-seed-2-command-state = "dsi_hs_mode";
				qcom,mdss-dsi-seed-3-command-state = "dsi_hs_mode";
				qcom,mdss-dsi-seed-0-switch-command-state = "dsi_hs_mode";
				qcom,mdss-dsi-seed-1-switch-command-state = "dsi_hs_mode";
				qcom,mdss-dsi-seed-2-switch-command-state = "dsi_hs_mode";
				qcom,mdss-dsi-seed-off-command-state = "dsi_hs_mode";
				qcom,mdss-dsi-fps-switch-command-state = "dsi_hs_mode";
				qcom,compression-mode = "dsc";
				qcom,mdss-dsc-slice-height = <30>;
				qcom,mdss-dsc-slice-width = <540>;
				qcom,mdss-dsc-slice-per-pkt = <2>;
				qcom,mdss-dsc-bit-per-component = <8>;
				qcom,mdss-dsc-bit-per-pixel = <8>;
				qcom,mdss-dsc-block-prediction-enable;
			};
		};
	};
};

&dsi_oplus21617samsung_ams662zs01_1080_2400_cmd_dvt {
	qcom,panel-supply-entries = <&dsi_panel_pwr_supply_21147>;
	qcom,mdss-dsi-panel-controller = <&mdss_dsi0>;
	qcom,mdss-dsi-bl-pmic-control-type = "bl_ctrl_dcs";
	qcom,mdss-dsi-bl-min-level = <1>;
	qcom,mdss-dsi-bl-normal-max-level = <2047>;
	qcom,mdss-dsi-bl-max-level = <4095>;
	qcom,mdss-brightness-normal-max-level = <2047>;
	qcom,mdss-brightness-max-level = <4095>;
	qcom,mdss-brightness-default-level = <400>;
	qcom,bl-update-flag = "delay_until_first_frame";
	qcom,platform-te-gpio = <&tlmm 82 0>;
	qcom,platform-reset-gpio = <&tlmm 24 0>;
	qcom,platform-panel-vddr-aod-en-gpio = <&tlmm 163 0>;
	qcom,mdss-dsi-reset-sequence = <0 0>, <0 1>, <1 6>;
	qcom,ulps-enabled;
	qcom,dsi-dyn-clk-enable;
	qcom,dsi-dyn-clk-list = <800000000 830000000>;
	qcom,dsi-select-clocks = "mux_byte_clk0", "mux_pixel_clk0",
						"src_byte_clk0", "src_pixel_clk0",
						"shadow_byte_clk0", "shadow_pixel_clk0";
	oplus,osc-support;
	oplus,mdss-dsi-osc-clk-mode0-rate = <180300>;
	oplus,mdss-dsi-osc-clk-mode1-rate = <182300>;
	qcom,mdss-dsi-dc-backlight-level = <1100>;
	oplus,apollo-sync-brightness-level = <711>;
	oplus,dsi-fod-brightness = <0 0xff>,
			<2 0xf2>,
			<4 0xf1>,
			<6 0xf0>,
			<8 0xee>,
			<10 0xee>,
			<20 0xed>,
			<40 0xec>,
			<60 0xeb>,
			<90 0xea>,
			<140 0xe9>,
			<200 0xe5>,
			<300 0xdc>,
			<450 0xcc>,
			<600 0xbc>,
			<750 0xac>,
			<900 0x9a>,
			<1050 0x8a>,
			<1200 0x7a>,
			<1400 0x68>,
			<1600 0x4a>,
			<1800 0x36>,
			<2047 0x1a>;

	oplus,dsi-dc-brightness = <0 255>,
			<1 255>,
			<4 248>,
			<8 247>,
			<35 245>,
			<105 243>,
			<195 240>,
			<235 238>,
			<305 233>,
			<400 225>,
			<500 215>,
			<580 205>,
			<591 195>,
			<660 175>,
			<720 155>,
			<780 135>,
			<825 115>,
			<865 95>,
			<900 76>,
			<963 55>,
			<1000 38>,
			<1050 18>,
			<1100 0>;
/*
	oplus,dsi-brightness-remapping = <4    4>,
			<5    5>,
			<6    6>,
			<7    7>,
			<10   10>,
			<244  19>,
			<373  49>,
			<493  90>,
			<585  130>,
			<663  171>,
			<731  212>,
			<792  253>,
			<847  294>,
			<899  335>,
			<948  376>,
			<993  417>,
			<1036 458>,
			<1078 499>,
			<1117 540>,
			<1155 581>,
			<1191 622>,
			<1226 663>,
			<1260 704>,
			<1293 745>,
			<1325 786>,
			<1356 826>,
			<1386 867>,
			<1415 908>,
			<1444 949>,
			<1472 990>,
			<1499 1031>,
			<1526 1072>,
			<1552 1113>,
			<1578 1154>,
			<1603 1195>,
			<1628 1236>,
			<1652 1277>,
			<1676 1318>,
			<1699 1359>,
			<1722 1400>,
			<1745 1441>,
			<1767 1482>,
			<1789 1522>,
			<1811 1563>,
			<1833 1604>,
			<1854 1645>,
			<1875 1686>,
			<1895 1727>,
			<1915 1768>,
			<1935 1809>,
			<1955 1850>,
			<1975 1891>,
			<1994 1932>,
			<2013 1973>,
			<2032 2014>,
			<2043 2038>,
			<2045 2042>,
			<2047 2047>,
			<4095 4095>;
*/
	qcom,mdss-dsi-display-timings {
		timing@0 {
				qcom,mdss-dsi-panel-phy-timings = [00 1D 07 07 17 16 07 07 08 02 04 00 19 0C];
				qcom,display-topology = <1 1 1>,<2 2 1>;
				qcom,default-topology-index = <0>;
		};
		timing@1 {
				qcom,mdss-dsi-panel-phy-timings = [00 1D 07 07 17 22 07 07 08 02 04 00 19 0C];
				qcom,display-topology = <1 1 1>,<2 2 1>;
				qcom,default-topology-index = <0>;
		};
	};
};

&dsi_oplus21617samsung_ams662zs01_1080_2400_cmd_dvt {
	pxlw,soft-iris-enable;
	oplus,apollo_backlight_enable;
	//oplus,color_srgb_status;
};

&dsi_oplus21617samsung_ams662zs01_1080_2400_cmd_dvt {
	qcom,panel_voltage_vddi_name = "vddio";
	qcom,panel_voltage_vddi = <0 1800000 1850000 1950000>;
	qcom,panel_voltage_vddr_name = "vddio";
	qcom,panel_voltage_vddr = <1 1800000 1850000 1950000>;
};
